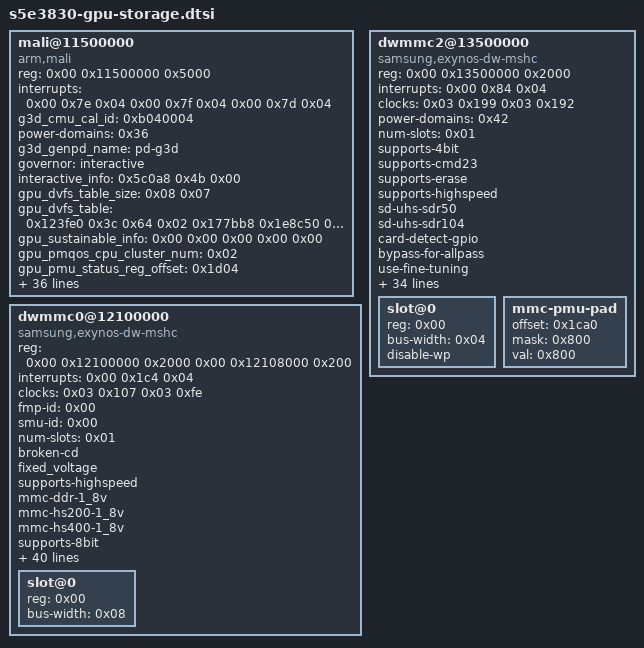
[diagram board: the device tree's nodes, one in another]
/* Samsung Exynos 850 (S5E3830) - Mali GPU and MMC hosts */

	mali@11500000 {
		compatible = "arm,mali";
		reg = <0x00 0x11500000 0x5000>;
		interrupts = <0x00 0x7e 0x04 0x00 0x7f 0x04 0x00 0x7d 0x04>;
		interrupt-names = "JOB\0MMU\0GPU";
		g3d_cmu_cal_id = <0xb040004>;
		power-domains = <0x36>;
		g3d_genpd_name = "pd-g3d";
		#cooling-cells = <0x02>;
		governor = "interactive";
		interactive_info = <0x5c0a8 0x4b 0x00>;
		gpu_dvfs_table_size = <0x08 0x07>;
		gpu_dvfs_table = <0x123fe0 0x3c 0x64 0x02 0x177bb8 0x1e8c50 0x00 0x10dc68 0x34 0x46 0x02 0x177bb8 0x1e8c50 0x00 0xf4628 0x38 0x41 0x02 0x177bb8 0x163780 0x00 0xd32e8 0x32 0x4b 0x02 0x177bb8 0x163780 0x00 0xb8150 0x2c 0x46 0x02 0x14a140 0x13d620 0x00 0x91ff0 0x22 0x3e 0x02 0xf78f0 0xe7b08 0x00 0x69b68 0x18 0x37 0x02 0xce4c8 0x9eb10 0x00 0x5c0a8 0x00 0x30 0x01 0xa50a0 0x854d0 0x00>;
		gpu_sustainable_info = <0x00 0x00 0x00 0x00 0x00>;
		gpu_pmqos_cpu_cluster_num = <0x02>;
		gpu_pmu_status_reg_offset = <0x1d04>;
		gpu_pmu_status_local_pwr_mask = <0x01>;
		gpu_max_clock = <0x123fe0>;
		gpu_max_clock_limit = <0x123fe0>;
		gpu_min_clock = <0x5c0a8>;
		gpu_dvfs_start_clock = <0x5c0a8>;
		gpu_dvfs_bl_config_clock = <0x5c0a8>;
		gpu_default_voltage = "\0\f5";
		gpu_cold_minimum_vol = <0x00>;
		gpu_voltage_offset_margin = <0x927c>;
		gpu_tmu_control = <0x01>;
		gpu_temp_throttling_level_num = <0x06>;
		gpu_temp_throttling = <0x91ff0 0x69b68 0x5c0a8 0x26160 0x186a0 0x186a0>;
		gpu_power_coeff = <0x271>;
		gpu_dvfs_time_interval = <0x05>;
		gpu_default_wakeup_lock = <0x01>;
		gpu_dynamic_abb = <0x00>;
		gpu_early_clk_gating = <0x00>;
		gpu_dvs = <0x00>;
		gpu_inter_frame_pm = <0x00>;
		gpu_perf_gathering = <0x00>;
		gpu_runtime_pm_delay_time = <0x32>;
		gpu_dvfs_polling_time = <0x1e>;
		gpu_pmqos_int_disable = <0x01>;
		gpu_pmqos_mif_max_clock = <0x1ff3b0>;
		gpu_pmqos_mif_max_clock_base = <0x9eb10>;
		gpu_cl_dvfs_start_base = <0x5c0a8>;
		gpu_debug_level = <0x03>;
		gpu_trace_level = <0x08>;
		gpu_mo_min_clock = <0x5c0a8>;
		gpu_boost_gpu_min_lock = <0x00>;
		gpu_boost_egl_min_lock = <0x1c9080>;
		gpu_vk_boost_max_lock = <0x4f588>;
		gpu_vk_boost_mif_min_lock = <0xf78f0>;
		gpu_bts_support = <0x01>;
		gpu_power_off_clock = <0x5c0a8>;
		phandle = <0xaf>;
	};

	dwmmc0@12100000 {
		compatible = "samsung,exynos-dw-mshc";
		#address-cells = <0x01>;
		#size-cells = <0x00>;
		reg = <0x00 0x12100000 0x2000 0x00 0x12108000 0x200>;
		reg-names = "dw_mmc\0cqhci_mem";
		interrupts = <0x00 0x1c4 0x04>;
		clocks = <0x03 0x107 0x03 0xfe>;
		clock-names = "ciu\0ciu_gate";
		fmp-id = <0x00>;
		smu-id = <0x00>;
		status = "okay";
		num-slots = <0x01>;
		broken-cd;
		fixed_voltage;
		supports-highspeed;
		mmc-ddr-1_8v;
		mmc-hs200-1_8v;
		mmc-hs400-1_8v;
		supports-8bit;
		supports-cmd23;
		supports-erase;
		extended-tmout;
		support-cmd-logging;
		mmc-hs400-enhanced-strobe;
		card-init-hwacg-ctrl;
		qos-dvfs-level = <0x518b0>;
		data-timeout = <0x1f4>;
		hto-timeout = <0x50>;
		enable-ulp-mode;
		support-cmdq;
		mmc-inline-crypt;
		fifo-depth = <0x40>;
		non-removable;
		desc-size = <0x04>;
		card-detect-delay = <0xc8>;
		samsung,dw-mshc-ciu-div = <0x03>;
		samsung,dw-mshc-txdt-crc-timer-fastlimit = <0x34>;
		samsung,dw-mshc-txdt-crc-timer-initval = <0x38>;
		samsung,dw-mshc-hs400-tx-delay-line = <0x40>;
		samsung,dw-mshc-hs400-delay-line = <0x60>;
		samsung,dw-mshc-sdr-timing = <0x03 0x00 0x04 0x00>;
		samsung,dw-mshc-ddr-timing = <0x03 0x00 0x04 0x02>;
		samsung,dw-mshc-hs200-timing = <0x03 0x00 0x03 0x00>;
		samsung,dw-mshc-hs400-timing = <0x01 0x00 0x02 0x00>;
		samsung,dw-mshc-hs400-ulp-timing = <0x03 0x00 0x04 0x02>;
		num-ref-clks = <0x0c>;
		ciu_clkin = <0x19 0x32 0x32 0x19 0x32 0x64 0xc8 0x32 0x32 0xc8 0xc8 0xc8>;
		clk-drive-number = <0x04>;
		pinctrl-names = "default\0fast-slew-rate-1x\0fast-slew-rate-2x\0fast-slew-rate-3x\0fast-slew-rate-4x";
		pinctrl-0 = <0x37 0x38 0x39 0x3a 0x3b 0x3c 0x3d>;
		pinctrl-1 = <0x3e>;
		pinctrl-2 = <0x3f>;
		pinctrl-3 = <0x40>;
		pinctrl-4 = <0x41>;
		phandle = <0x104>;

		slot@0 {
			reg = <0x00>;
			bus-width = <0x08>;
		};
	};

	dwmmc2@13500000 {
		compatible = "samsung,exynos-dw-mshc";
		#address-cells = <0x01>;
		#size-cells = <0x00>;
		reg = <0x00 0x13500000 0x2000>;
		reg-names = "dw_mmc";
		interrupts = <0x00 0x84 0x04>;
		clocks = <0x03 0x199 0x03 0x192>;
		clock-names = "ciu\0ciu_gate";
		power-domains = <0x42>;
		status = "okay";
		num-slots = <0x01>;
		supports-4bit;
		supports-cmd23;
		supports-erase;
		supports-highspeed;
		sd-uhs-sdr50;
		sd-uhs-sdr104;
		card-detect-gpio;
		bypass-for-allpass;
		use-fine-tuning;
		card-init-hwacg-ctrl;
		skip-init-mmc-scan;
		use-runtime-pm;
		skip-init-no-tray;
		fifo-depth = <0x40>;
		data-timeout = <0xc8>;
		hto-timeout = <0x50>;
		desc-size = <0x04>;
		ssc-rate-mfr = <0x0c>;
		ssc-rate-mrr = <0x03>;
		card-detect-delay = <0x190>;
		samsung,dw-mshc-ciu-div = <0x03>;
		clock-frequency = <0x2faf0800>;
		samsung,dw-mshc-sdr-timing = <0x03 0x00 0x02 0x00>;
		samsung,dw-mshc-hs-timing = <0x03 0x00 0x02 0x01>;
		samsung,dw-mshc-ddr-timing = <0x03 0x00 0x02 0x01>;
		samsung,dw-mshc-sdr50-timing = <0x03 0x00 0x03 0x02>;
		samsung,dw-mshc-sdr104-timing = <0x03 0x00 0x03 0x00>;
		num-ref-clks = <0x09>;
		ciu_clkin = <0x19 0x32 0x32 0x19 0x32 0x64 0xc8 0x32 0x32>;
		clk-drive-number = <0x06>;
		pinctrl-names = "init\0fast-slew-rate-1x\0fast-slew-rate-1_5x\0fast-slew-rate-2x\0fast-slew-rate-2_5x\0fast-slew-rate-3x\0fast-slew-rate-4x\0pins-as-pdn\0pins-as-func";
		pinctrl-1 = <0x43>;
		pinctrl-2 = <0x44>;
		pinctrl-3 = <0x45>;
		pinctrl-4 = <0x46>;
		pinctrl-5 = <0x47>;
		pinctrl-6 = <0x48>;
		pinctrl-7 = <0x49>;
		pinctrl-8 = <0x4a 0x4b 0x4c 0x4d>;
		phandle = <0x105>;

		slot@0 {
			reg = <0x00>;
			bus-width = <0x04>;
			disable-wp;
		};

		mmc-pmu-pad {
			offset = <0x1ca0>;
			mask = <0x800>;
			val = <0x800>;
		};
	};
